# Musca_S1 register map
Vendor: ARM Ltd.; Series: ARMv8-M Mainline; File version: 1.0
CPU: CM33 r0p1, little endian, MPU, no FPU, 3 interrupt priority bits, 8 SAU regions
Registers are 32-bit, read-write, reset 0x0 unless marked. A register's access mark holds for its fields unless they carry their own. Offsets are from the block's base; [hi:lo] are bit positions; 'fields as' and 'values as' point back to an identical list.

## SAU — Security Attribution Unit
Base 0xE000EDD0
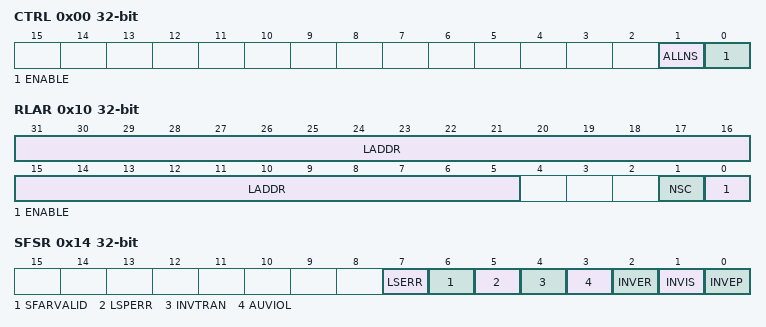
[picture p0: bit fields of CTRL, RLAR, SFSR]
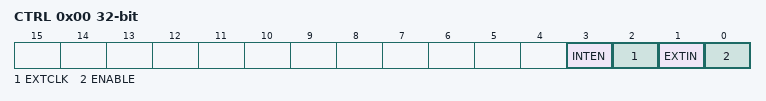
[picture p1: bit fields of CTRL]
0x00 CTRL — Control Register
  [1] ALLNS — Security attribution if SAU disabled
    0=Secure (Memory is marked as secure); 1=Non_Secure (Memory is marked as non-secure)
  [0] ENABLE
    0=Disable (SAU is disabled); 1=Enable (SAU is enabled)
0x04 TYPE ro
  [7:0] SREGION — Number of implemented SAU regions
0x08 RNR — Region Number Register
  [7:0] REGION — Currently selected SAU region
0x0C RBAR — Region Base Address Register
  [31:5] BADDR — Base Address
0x10 RLAR — Region Limit Address Register
  [31:5] LADDR — Limit Address
  [1] NSC — Non-Secure Callable
  [0] ENABLE — SAU Region enabled
0x14 SFSR — Secure Fault Status Register
  [7] LSERR — Lazy state error flag
  [6] SFARVALID — Secure fault address valid
  [5] LSPERR — Lazy state preservation error flag
  [4] INVTRAN — Invalid transition flag
  [3] AUVIOL — Attribution unit violation flag
  [2] INVER — Invalid exception return flag
  [1] INVIS — Invalid integrity signature flag
  [0] INVEP — Invalid entry pointd

## TIMER0
Base 0x40000000
Same registers: TIMER1 0x40001000, S32KTIMER 0x4002F000, TIMER0_Secure 0x50000000, TIMER1_Secure 0x50001000, S32KTIMER_Secure 0x5002F000
0x00 CTRL — Control Register
  [3] INTEN — Interrupt Enable
  [2] EXTCLK — External Clock Enable
  [1] EXTIN — External Input as Enable
  [0] ENABLE
0x04 VALUE — Current Timer Counter Value
0x08 RELOAD — Counter Reload Value
0x0C INTSTATUS ro — Timer Interrupt status Register
0x0C INTCLEAR wo write-1-clears (alternate view of INTSTATUS) — Timer Interrupt clear Register

## DUALTIMER
Base 0x40002000
Same registers: DUALTIMER_Secure 0x50002000
0x00 TIMER1LOAD
0x04 TIMER1VALUE ro reset 0xFFFFFFFF
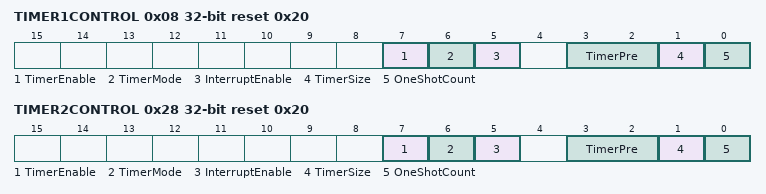
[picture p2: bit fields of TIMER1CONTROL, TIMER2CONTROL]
0x08 TIMER1CONTROL reset 0x20
  [7] TimerEnable — Timer Enable Enable bit
    0=Disable (Timer is disabled); 1=Enable (Timer is enabled)
  [6] TimerMode — Timer Mode bit
    0=Free-Running timer mode; 1=Periodic timer mode
  [5] InterruptEnable — Interrupt Enable bit
    0=Disable (Interrupt is disabled); 1=Enable (Interrupt is enabled)
  [3:2] TimerPre — Timer prescale bits
    0=divided by 1 (clock is divided by 1); 1=divided by 16 (clock is divided by 16); 2=divided by 256 (clock is divided by 256)
  [1] TimerSize — Selects 16-bit or 32- bit counter operation
    0=16-bit counter mode; 1=32-bit counter mode
  [0] OneShotCount — Selects one-shot or wrapping counter mode
    0=Wrapping counter mode; 1=One-shot counter mode
0x0C TIMER1INTCLR wo — Timer 1 Interrupt Clear Register
  [0] INT write-1-clears — Interrupt
0x10 TIMER1RIS ro — Timer 1 Raw Interrupt Status Register
  [0] RIS — Raw Timer Interrupt
0x14 TIMER1MIS ro — Timer 1 Mask Interrupt Status Register
  [0] MIS — Masked Timer Interrupt
0x18 TIMER1BGLOAD — Timer 1 Background Load Register
0x20 TIMER2LOAD
0x24 TIMER2VALUE ro reset 0xFFFFFFFF
0x28 TIMER2CONTROL reset 0x20
  fields as TIMER1CONTROL
0x2C TIMER2INTCLR wo — Timer 2 Interrupt Clear Register
  [0] INT write-1-clears — Interrupt
0x30 TIMER2RIS ro — Timer 2 Raw Interrupt Status Register
  [0] RIS — Raw Timer Interrupt
0x34 TIMER2MIS ro — Timer 2 Mask Interrupt Status Register
  [0] MIS — Masked Timer Interrupt
0x38 TIMER2BGLOAD — Timer 2 Background Load Register

## GPTIMER — General-Purpose Timer
Base 0x4010B000
Same registers: GPTIMER_Secure 0x5010B000
0x00 GPTRESET ro — Control Reset Register
  [1:0] GPTRESET — CPU0 interrupt status
0x04 GPTINTM — Masked interrupt status Register
  [1:0] GPTINTM — Current masked status of the Interrupt
0x08 GPTINTC — Interrupt clear Register
  [1:0] GPTINTC — Writing 0b1 disables the ALARM[n] Interrupt
0x10 GPTALARM0 — ALARM0 data value Register
  [31:0] GPTALARM0_DATA — Value that triggers the ALARM0 interrupt when the counter reaches that value
0x14 GPTALARM1 — ALARM1 data value Register
  [31:0] GPTALARM1_DATA — Value that triggers the ALARM1 interrupt when the counter reaches that value
0x18 GPTINTR ro — Raw interrupt status Register
  [2:0] GPTINTR — Raw interrupt state, before masking of GPTINTR Interrupt
0x1C GPTCOUNTER ro — Counter data value Register
  [31:0] GPTCOUNTER — Current value of 32-bit Timer Counter
